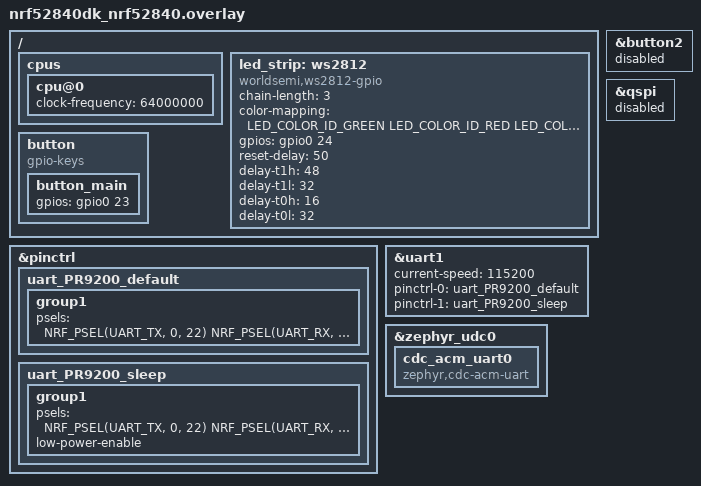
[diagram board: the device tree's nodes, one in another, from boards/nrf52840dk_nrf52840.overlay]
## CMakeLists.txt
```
# SPDX-License-Identifier: Apache-2.0

cmake_minimum_required(VERSION 3.20.0)

find_package(Zephyr REQUIRED HINTS $ENV{ZEPHYR_BASE})
project(UB010.0.1_demo)

target_include_directories(app PRIVATE inc)

FILE(GLOB app_sources src/*.c)
target_sources(app PRIVATE 
    ${ZEPHYR_BASE}/../modules/debug/segger/SEGGER/SEGGER_RTT_printf.c
    ${app_sources}
)
```

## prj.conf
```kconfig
CONFIG_USE_SEGGER_RTT=y
CONFIG_SEGGER_RTT_PRINTF_BUFFER_SIZE=16000
CONFIG_SEGGER_RTT_BUFFER_SIZE_UP=16000

# BUTTON
CONFIG_GPIO=y

# LEDS
CONFIG_LED_STRIP=y

# UART
CONFIG_SERIAL=y
CONFIG_UART_INTERRUPT_DRIVEN=y

# USB CDC
CONFIG_USB_DEVICE_STACK=y
CONFIG_USB_DEVICE_PRODUCT="UHFS Demo V0.1"
CONFIG_USB_DEVICE_PID=0x0001
CONFIG_USB_DEVICE_INITIALIZE_AT_BOOT=n

# I2C
CONFIG_I2C=y
```

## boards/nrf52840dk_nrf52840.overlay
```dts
#include <zephyr/dt-bindings/gpio/gpio.h>
#include <zephyr/dt-bindings/led/led.h>


&pinctrl {
    uart_PR9200_default: uart_PR9200_default {
        group1 {
            psels = <
                NRF_PSEL(UART_TX, 0, 22)
                NRF_PSEL(UART_RX, 0, 21)
            >;
        };
    };

    uart_PR9200_sleep: uart_PR9200_sleep {
        group1 {
            psels = <
                NRF_PSEL(UART_TX, 0, 22)
                NRF_PSEL(UART_RX, 0, 21)
            >;
            low-power-enable;
        };
    };
};


/ {
    cpus 
	{
        cpu@0 
		{
        	clock-frequency = <64000000>;
        };
    };

	led_strip: ws2812 
	{
		compatible = "worldsemi,ws2812-gpio";

		chain-length = <3>; /* arbitrary */
		color-mapping = <LED_COLOR_ID_GREEN LED_COLOR_ID_RED LED_COLOR_ID_BLUE>;

		gpios = <&gpio0 24 0>;

		reset-delay = <50>;
		delay-t1h = <48>;
		delay-t1l = <32>;
		delay-t0h = <16>;
		delay-t0l = <32>;
	};	

	button
	{
		compatible = "gpio-keys";
		button_main: button_main
		{
			gpios = <&gpio0 23 0>;
		};
	};
};




&uart1
{
	current-speed = <115200>;

    status = "okay";
    pinctrl-0 = <&uart_PR9200_default>;
    pinctrl-1 = <&uart_PR9200_sleep>;
    pinctrl-names = "default", "sleep";
};

&zephyr_udc0 {
	cdc_acm_uart0 {
		compatible = "zephyr,cdc-acm-uart";
	};
};




&button2
{
	status = "disabled";
};

&qspi 
{
	status = "disabled";
};
```

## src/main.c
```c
#include <SEGGER_RTT.h>

#include <zephyr/kernel.h>
#include <zephyr/drivers/gpio.h>
#include <zephyr/drivers/led_strip.h>


#include "led_part.h"
#include "button_part.h"
#include "uart_part.h"
#include "usb_part.h"


void animation_work_handler(struct k_work *work) 
{
	led_updatePixeles(&COLOR_BLACK, &COLOR_BLACK, &COLOR_BLACK);
	k_msleep(200);
	led_updatePixeles(&COLOR_BLUE, &COLOR_BLACK, &COLOR_BLACK);
	k_msleep(200);
	led_updatePixeles(&COLOR_GREEN, &COLOR_BLUE, &COLOR_BLACK);
	k_msleep(200);
	led_updatePixeles(&COLOR_RED, &COLOR_GREEN, &COLOR_BLUE);
	k_msleep(200);
}
K_WORK_DEFINE(animation_work, animation_work_handler);


void button_callback_handler(const struct device *port, struct gpio_callback *cb, gpio_port_pins_t pins) 
{
	if (pins & BIT(button_getPin()))
	{
		if (button_getState() == 0) 
		{
			k_work_submit(&animation_work);
		}
	}
}


static void uart_rx_handler(const struct device *dev, void *user_data)
{
	ARG_UNUSED(user_data);

    uint8_t byteBuf = 0;
    if (uart_irq_update(dev) && uart_irq_rx_ready(dev)) 
	{
		while (uart_fifo_read(dev, &byteBuf, 1))
		{
			usb_sendByte(byteBuf); // Эхо от UARTа к USB
        }
	}	
}


static void usb_rx_handler(const struct device *dev, void *user_data)
{
	ARG_UNUSED(user_data);

    uint8_t byteBuf = 0;
    if (uart_irq_update(dev) && uart_irq_rx_ready(dev)) 
	{
		while (uart_fifo_read(dev, &byteBuf, 1))
		{
            uart_sendByte(byteBuf); // Эхо от USB к UARTу
        }
	}	
}


int main(void)
{
	led_begin();
	button_begin(button_callback_handler);
	
	uart_begin(uart_rx_handler);
	usb_begin(usb_rx_handler);

	while (1) 
	{	
		k_msleep(1000);
	}

	return 0;
}
```

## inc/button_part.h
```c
#pragma once

#include <SEGGER_RTT.h>

#include <zephyr/kernel.h>
#include <zephyr/drivers/gpio.h>



int button_begin(gpio_callback_handler_t interrupt_handler);
int button_getPin();

int button_getState();
```

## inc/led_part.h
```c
#pragma once

#include <SEGGER_RTT.h>

#include <zephyr/kernel.h>
#include <zephyr/drivers/led_strip.h>


#define COLOR(red, green, blue) (struct led_rgb){ .r = red, .g = green, .b = blue }

#define COLOR_BLACK		COLOR(0, 0, 0)
#define COLOR_BLUE		COLOR(0, 0, 255)
#define COLOR_RED		COLOR(255, 0, 0)
#define COLOR_PINK      COLOR(255, 0, 255)
#define COLOR_GREEN		COLOR(0, 255, 0)
#define COLOR_CYAN      COLOR(0, 255, 255)
#define COLOR_YELLOW    COLOR(255, 255, 0)
#define COLOR_WHITE		COLOR(255, 255, 255)



int led_begin();

void led_setPixel(int id, struct led_rgb *pixel);
struct led_rgb *led_getPixel(int id);

int led_update();
int led_updatePixeles(struct led_rgb *px0, struct led_rgb *px1, struct led_rgb *px2);
```

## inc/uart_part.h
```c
#pragma once

#include <SEGGER_RTT.h>

#include <zephyr/kernel.h>
#include <zephyr/drivers/uart.h>



int uart_begin(uart_irq_callback_user_data_t rx_callback);
void uart_sendByte(uint8_t data);
```

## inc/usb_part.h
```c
#pragma once

#include <SEGGER_RTT.h>

#include <zephyr/kernel.h>

#include <zephyr/drivers/uart.h>

#include <zephyr/usb/usb_device.h>
#include <zephyr/usb/usbd.h>


int usb_begin(uart_irq_callback_user_data_t rx_callback);
void usb_sendByte(uint8_t data);
```

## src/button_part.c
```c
#include "button_part.h"

static const struct gpio_dt_spec button = GPIO_DT_SPEC_GET_OR(DT_NODELABEL(button_main), gpios, {0});
static struct gpio_callback button_callback;


int button_begin(gpio_callback_handler_t interrupt_handler) 
{
	int err = 0;
	
	if (!gpio_is_ready_dt(&button)) 
	{
		SEGGER_RTT_printf(0, " --- BTN ERROR --- : Button Device is Not Ready!\n");
		return -1;
	}


	err = gpio_pin_configure_dt(&button, GPIO_INPUT | GPIO_PULL_UP);
	if (err < 0) 
	{
		SEGGER_RTT_printf(0, " --- BTN ERROR --- : Button Config Failed!\n");
		return err;
	}

	err = gpio_pin_interrupt_configure_dt(&button, GPIO_INT_EDGE_BOTH);
	if (err < 0) 
	{
		SEGGER_RTT_printf(0, " --- BTN ERROR --- : Button Interrupt Config Failed!\n");
		return err;
	}

	gpio_init_callback(&button_callback, interrupt_handler, BIT(button.pin));
	err = gpio_add_callback_dt(&button, &button_callback);
	if (err < 0) 
	{
		SEGGER_RTT_printf(0, " --- BTN ERROR --- : Button Adding Callback Failed!\n");
		return err;
	}

	return 0;
}

int button_getPin() 
{
    return button.pin;
}


int button_getState() 
{
    return gpio_pin_get_dt(&button);
}
```

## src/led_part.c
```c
#include "led_part.h"

static const struct device *const led_strip = DEVICE_DT_GET(DT_NODELABEL(led_strip));
#define led_strip_len 	DT_PROP(DT_NODELABEL(led_strip), chain_length)

static struct led_rgb led_pixeles[led_strip_len];



int led_begin() 
{
	if (!device_is_ready(led_strip)) 
	{
		SEGGER_RTT_printf(0, " --- LED ERROR --- : Strip Device is Not Ready!\n");
		return -1;
	}

	return 0;
}


void led_setPixel(int id, struct led_rgb *pixel)
{
    if (id >= led_strip_len)
    {
        return;
    }

	led_pixeles[id].r = pixel->r;
	led_pixeles[id].g = pixel->g;
	led_pixeles[id].b = pixel->b;
}


struct led_rgb *led_getPixel(int id) 
{
    if (id >= led_strip_len)
    {
        return NULL;
    }

    return &led_pixeles[id];
}


int led_update()
{
    return led_strip_update_rgb(led_strip, led_pixeles, led_strip_len);
}


int led_updatePixeles(struct led_rgb *px0, struct led_rgb *px1, struct led_rgb *px2) 
{
    led_setPixel(0, px0);
    led_setPixel(1, px1);
    led_setPixel(2, px2);
    return led_update();
}
```

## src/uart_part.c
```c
#include "uart_part.h"



const struct device *uart = DEVICE_DT_GET(DT_NODELABEL(uart1));


int uart_begin(uart_irq_callback_user_data_t rx_callback) 
{
    int err = 0;


    if (!device_is_ready(uart)) 
    {
        SEGGER_RTT_printf(0, " --- UART ERR --- : UART Device is not Ready!\n");
        return -1;
    }

	// Устанавливаем и включаем прерывание
	err = uart_irq_callback_set(uart, rx_callback);
	if (err != 0) 
	{
        SEGGER_RTT_printf(0, " --- UART ERR --- : RX Callback set Failed!\n");
		return err;
	}
	uart_irq_rx_enable(uart);	

    return 0;
}

void uart_sendByte(uint8_t data) 
{
    uart_poll_out(uart, data);
}
```

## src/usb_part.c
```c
#include "usb_part.h"



const struct device *const usb_cdc = DEVICE_DT_GET_ONE(zephyr_cdc_acm_uart);


int usb_begin(uart_irq_callback_user_data_t rx_callback) 
{
	int err = 0;

	// Инициализация USB 
    if (!device_is_ready(usb_cdc)) 
	{
        SEGGER_RTT_printf(0, " --- USB CDC ERR --- : CDC ACM device not ready\n");
        return -ENODEV;
    }	

	err = usb_enable(NULL);
	if (err != 0) 
	{
		SEGGER_RTT_printf(0, " --- USB CDC ERR --- : Failed to enable USB\n");
		return err;
	}

	// Устанавливаем и включаем прерывание
	err = uart_irq_callback_set(usb_cdc, rx_callback);
	if (err != 0) 
	{
		SEGGER_RTT_printf(0, " --- USB CDC ERR --- : RX Callback set Failed\n");
		return err;
	}
	uart_irq_rx_enable(usb_cdc);	

	SEGGER_RTT_printf(0, " --- USB CDC --- :  Successful Initialized!\n");
	return 0;
}

void usb_sendByte(uint8_t data)
{
	uart_poll_out(usb_cdc, data);
}
```
